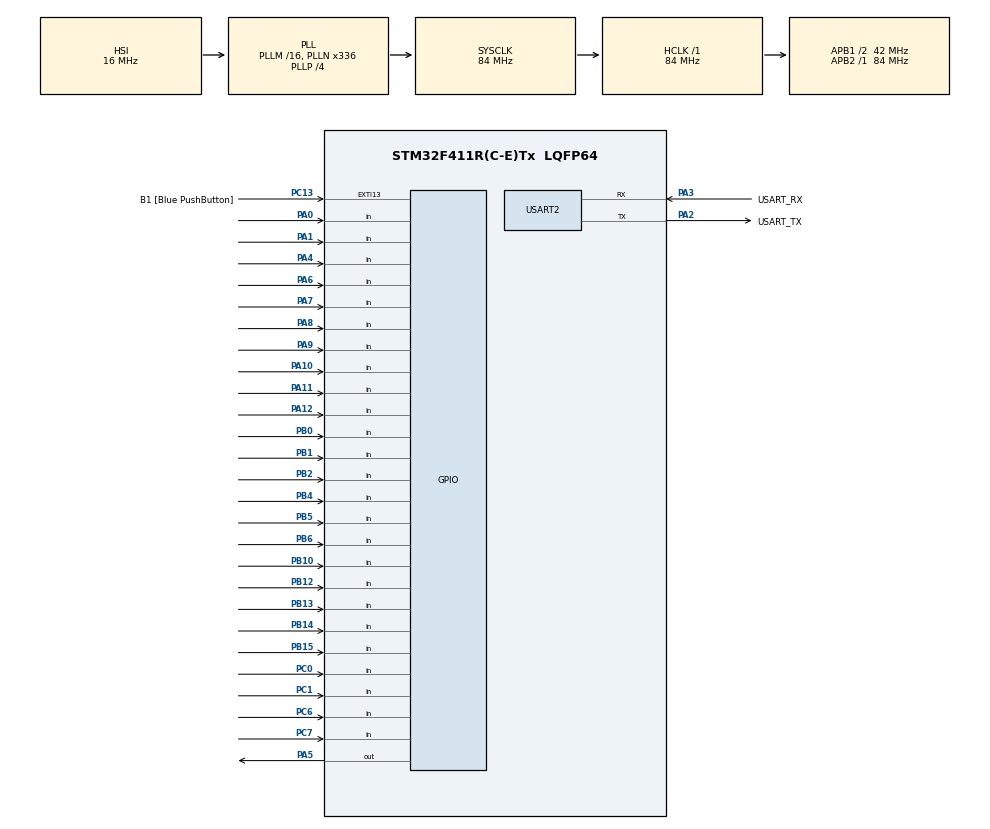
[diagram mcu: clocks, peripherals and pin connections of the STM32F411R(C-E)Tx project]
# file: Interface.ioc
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FREERTOS.Tasks01=defaultTask,24,128,StartDefaultTask,Default,NULL,Dynamic,NULL,NULL;Timer,48,128,Start_Timer,As weak,NULL,Dynamic,NULL,NULL;Pub_Pin_Read,49,128,Start_Pub_Pin_Read,As weak,NULL,Dynamic,NULL,NULL
FREERTOS.configENABLE_FPU=1
FREERTOS.configUSE_NEWLIB_REENTRANT=1
Mcu.Family=STM32F4
Mcu.Name=STM32F411R(C-E)Tx
Mcu.Package=LQFP64
NVIC.EXTI15_10_IRQn=true\:5\:0\:false\:false\:true\:true\:true\:true
NVIC.PriorityGroup=NVIC_PRIORITYGROUP_4
NVIC.TIM2_IRQn=true\:15\:0\:false\:false\:true\:false\:false\:true
NVIC.TimeBase=TIM2_IRQn
NVIC.TimeBaseIP=TIM2
PA0-WKUP.Signal=GPIO_Input
PA1.Signal=GPIO_Input
PA10.Signal=GPIO_Input
PA11.Signal=GPIO_Input
PA12.Signal=GPIO_Input
PA13.GPIO_Label=TMS
PA13.Mode=Serial_Wire
PA13.Signal=SYS_JTMS-SWDIO
PA14.GPIO_Label=TCK
PA14.Mode=Serial_Wire
PA14.Signal=SYS_JTCK-SWCLK
PA2.GPIO_Label=USART_TX
PA2.Mode=Asynchronous
PA2.Signal=USART2_TX
PA3.GPIO_Label=USART_RX
PA3.Mode=Asynchronous
PA3.Signal=USART2_RX
PA4.Signal=GPIO_Input
PA5.Signal=GPIO_Output
PA6.Signal=GPIO_Input
PA7.Signal=GPIO_Input
PA8.Signal=GPIO_Input
PA9.Signal=GPIO_Input
PB0.Signal=GPIO_Input
PB1.Signal=GPIO_Input
PB10.Signal=GPIO_Input
PB12.Signal=GPIO_Input
PB13.Signal=GPIO_Input
PB14.Signal=GPIO_Input
PB15.Signal=GPIO_Input
PB2.Signal=GPIO_Input
PB3.GPIO_Label=SWO
PB3.Signal=SYS_JTDO-SWO
PB4.Signal=GPIO_Input
PB5.Signal=GPIO_Input
PB6.Signal=GPIO_Input
PC0.Signal=GPIO_Input
PC1.Signal=GPIO_Input
PC13-ANTI_TAMP.GPIO_Label=B1 [Blue PushButton]
PC13-ANTI_TAMP.GPIO_ModeDefaultEXTI=GPIO_MODE_IT_FALLING
PC13-ANTI_TAMP.Signal=GPXTI13
PC14-OSC32_IN.Mode=LSE-External-Oscillator
PC14-OSC32_IN.Signal=RCC_OSC32_IN
PC15-OSC32_OUT.Mode=LSE-External-Oscillator
PC15-OSC32_OUT.Signal=RCC_OSC32_OUT
PC6.Signal=GPIO_Input
PC7.Signal=GPIO_Input
PH0\ -\ OSC_IN.Mode=HSE-External-Clock-Source
PH0\ -\ OSC_IN.Signal=RCC_OSC_IN
PH1\ -\ OSC_OUT.Mode=HSE-External-Clock-Source
PH1\ -\ OSC_OUT.Signal=RCC_OSC_OUT
ProjectManager.HeapSize=0x200
ProjectManager.StackSize=0x400
ProjectManager.TargetToolchain=STM32CubeIDE
RCC.48MHZClocksFreq_Value=84000000
RCC.AHBFreq_Value=84000000
RCC.APB1CLKDivider=RCC_HCLK_DIV2
RCC.APB1Freq_Value=42000000
RCC.APB1TimFreq_Value=84000000
RCC.APB2Freq_Value=84000000
RCC.APB2TimFreq_Value=84000000
RCC.CortexFreq_Value=84000000
RCC.FLatency-AdvancedSettings=FLASH_LATENCY_2
RCC.HCLKFreq_Value=84000000
RCC.HSE_VALUE=8000000
RCC.HSI_VALUE=16000000
RCC.PLLN=336
RCC.PLLP=RCC_PLLP_DIV4
RCC.SYSCLKFreq_VALUE=84000000
RCC.SYSCLKSource=RCC_SYSCLKSOURCE_PLLCLK
RCC.VCOOutputFreq_Value=336000000
USART2.VirtualMode=VM_ASYNC
VP_FREERTOS_VS_CMSIS_V2.Mode=CMSIS_V2
VP_SYS_VS_tim2.Mode=TIM2
VP_TIM1_VS_ClockSourceINT.Mode=Internal
VP_TIM1_VS_ClockSourceITR.Mode=TriggerSource_ITR0
board=NUCLEO-F411RE

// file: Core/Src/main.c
/* USER CODE BEGIN Header */
/**
  ******************************************************************************
  * @file           : main.c
  * @brief          : Main program body
  ******************************************************************************
  * @attention
  *
  * Copyright (c) 2022 STMicroelectronics.
  * All rights reserved.
  *
  * This software is licensed under terms that can be found in the LICENSE file
  * in the root directory of this software component.
  * If no LICENSE file comes with this software, it is provided AS-IS.
  *
  ******************************************************************************
  */
/* USER CODE END Header */
#include "main.h"
#include "cmsis_os.h"
#include "tim.h"
#include "usart.h"
#include "gpio.h"

void SystemClock_Config(void);
void MX_FREERTOS_Init(void);

/* USER CODE BEGIN 0 */

struct TIM_TOG timer_tog;

/* USER CODE END 0 */

int main(void)
{

  /* MCU Configuration--------------------------------------------------------*/

  /* Reset of all peripherals, Initializes the Flash interface and the Systick. */
  HAL_Init();

  /* USER CODE BEGIN Init */
	timer_tog.state = 1;
	timer_tog.send_data = 0;

  /* USER CODE END Init */

  /* Configure the system clock */
  SystemClock_Config();

  /* Initialize all configured peripherals */
  MX_GPIO_Init();
  MX_USART2_UART_Init();
  MX_TIM1_Init();

  /* Init scheduler */
  osKernelInitialize();  /* Call init function for freertos objects (in freertos.c) */
  MX_FREERTOS_Init();
  /* Start scheduler */
  osKernelStart();

  /* We should never get here as control is now taken by the scheduler */
  /* Infinite loop */
  while (1)
  {

  }
}

void SystemClock_Config(void)
{
  RCC_OscInitTypeDef RCC_OscInitStruct = {0};
  RCC_ClkInitTypeDef RCC_ClkInitStruct = {0};

  /** Configure the main internal regulator output voltage
  */
  __HAL_RCC_PWR_CLK_ENABLE();
  __HAL_PWR_VOLTAGESCALING_CONFIG(PWR_REGULATOR_VOLTAGE_SCALE1);
  /** Initializes the RCC Oscillators according to the specified parameters
  * in the RCC_OscInitTypeDef structure.
  */
  RCC_OscInitStruct.OscillatorType = RCC_OSCILLATORTYPE_HSI;
  RCC_OscInitStruct.HSIState = RCC_HSI_ON;
  RCC_OscInitStruct.HSICalibrationValue = RCC_HSICALIBRATION_DEFAULT;
  RCC_OscInitStruct.PLL.PLLState = RCC_PLL_ON;
  RCC_OscInitStruct.PLL.PLLSource = RCC_PLLSOURCE_HSI;
  RCC_OscInitStruct.PLL.PLLM = 16;
  RCC_OscInitStruct.PLL.PLLN = 336;
  RCC_OscInitStruct.PLL.PLLP = RCC_PLLP_DIV4;
  RCC_OscInitStruct.PLL.PLLQ = 4;
  if (HAL_RCC_OscConfig(&RCC_OscInitStruct) != HAL_OK)
  {
    Error_Handler();
  }
  /** Initializes the CPU, AHB and APB buses clocks
  */
  RCC_ClkInitStruct.ClockType = RCC_CLOCKTYPE_HCLK|RCC_CLOCKTYPE_SYSCLK
                              |RCC_CLOCKTYPE_PCLK1|RCC_CLOCKTYPE_PCLK2;
  RCC_ClkInitStruct.SYSCLKSource = RCC_SYSCLKSOURCE_PLLCLK;
  RCC_ClkInitStruct.AHBCLKDivider = RCC_SYSCLK_DIV1;
  RCC_ClkInitStruct.APB1CLKDivider = RCC_HCLK_DIV2;
  RCC_ClkInitStruct.APB2CLKDivider = RCC_HCLK_DIV1;

  if (HAL_RCC_ClockConfig(&RCC_ClkInitStruct, FLASH_LATENCY_2) != HAL_OK)
  {
    Error_Handler();
  }
}

void HAL_TIM_PeriodElapsedCallback(TIM_HandleTypeDef *htim)
{
  if (htim->Instance == TIM2) {
    HAL_IncTick();
  }
}

void Error_Handler(void)
{
  __disable_irq();
  while (1)
  {
  }
}

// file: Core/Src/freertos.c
/* USER CODE BEGIN Header */
/**
  ******************************************************************************
  * File Name          : freertos.c
  * Description        : Code for freertos applications
  ******************************************************************************
  * @attention
  *
  * Copyright (c) 2022 STMicroelectronics.
  * All rights reserved.
  *
  * This software is licensed under terms that can be found in the LICENSE file
  * in the root directory of this software component.
  * If no LICENSE file comes with this software, it is provided AS-IS.
  *
  ******************************************************************************
  */
/* USER CODE END Header */

#include "FreeRTOS.h"
#include "task.h"
#include "main.h"
#include "cmsis_os.h"

/* Definitions for defaultTask */
osThreadId_t defaultTaskHandle;
const osThreadAttr_t defaultTask_attributes = {
  .name = "defaultTask",
  .stack_size = 128 * 4,
  .priority = (osPriority_t) osPriorityNormal,
};
/* Definitions for Timer */
osThreadId_t TimerHandle;
const osThreadAttr_t Timer_attributes = {
  .name = "Timer",
  .stack_size = 128 * 4,
  .priority = (osPriority_t) osPriorityRealtime,
};
/* Definitions for Pub_Pin_Read */
osThreadId_t Pub_Pin_ReadHandle;
const osThreadAttr_t Pub_Pin_Read_attributes = {
  .name = "Pub_Pin_Read",
  .stack_size = 128 * 4,
  .priority = (osPriority_t) osPriorityRealtime1,
};

void StartDefaultTask(void *argument);
void Start_Timer(void *argument);
void Start_Pub_Pin_Read(void *argument);

void MX_FREERTOS_Init(void); /* (MISRA C 2004 rule 8.1) */

void MX_FREERTOS_Init(void) {

  /* Create the thread(s) */
  /* creation of defaultTask */
  defaultTaskHandle = osThreadNew(StartDefaultTask, NULL, &defaultTask_attributes);

  /* creation of Timer */
  TimerHandle = osThreadNew(Start_Timer, NULL, &Timer_attributes);

  /* creation of Pub_Pin_Read */
  Pub_Pin_ReadHandle = osThreadNew(Start_Pub_Pin_Read, NULL, &Pub_Pin_Read_attributes);

}

void StartDefaultTask(void *argument)
{
  for(;;)
  {
    osDelay(1);
  }
}

__weak void Start_Timer(void *argument)
{
  for(;;)
  {
    osDelay(1);
  }
}

__weak void Start_Pub_Pin_Read(void *argument)
{
  for(;;)
  {
    osDelay(1);
  }
}
